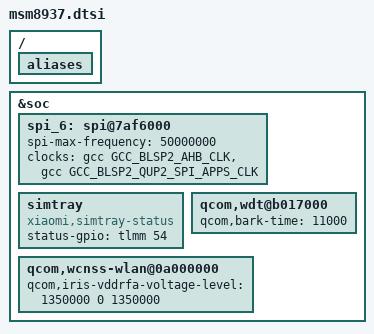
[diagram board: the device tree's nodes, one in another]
/ {
	aliases {
		/delete-property/ i2c4;
	};
};

&soc {
	/delete-node/ i2c@78b8000;

        spi_6: spi@7af6000 { /* BLSP2 QUP2 */
                spi-max-frequency = <50000000>;
		clocks = <&gcc GCC_BLSP2_AHB_CLK>,
			<&gcc GCC_BLSP2_QUP2_SPI_APPS_CLK>;
		status = "okay";
	};
	simtray {
		compatible = "xiaomi,simtray-status";
		status-gpio = <&tlmm 54 0x00>;
	};
	qcom,wdt@b017000 {
		qcom,bark-time = <11000>;
	};
	qcom,wcnss-wlan@0a000000 {
		qcom,iris-vddrfa-voltage-level = <1350000 0 1350000>;
	};
};
